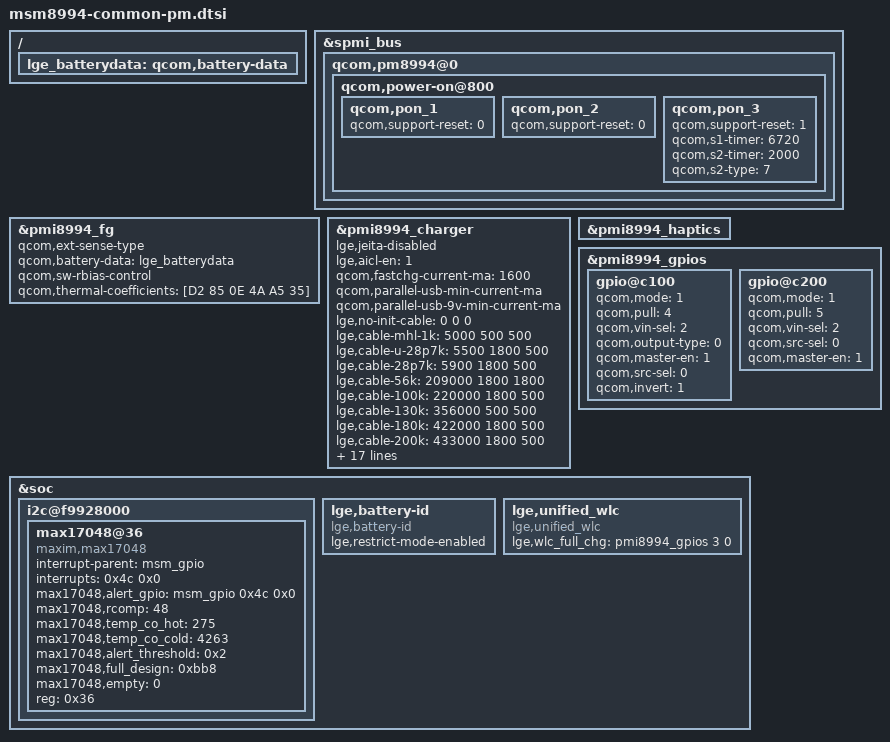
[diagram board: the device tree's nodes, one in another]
&spmi_bus {
	qcom,pm8994@0 {
		qcom,power-on@800 {
			qcom,pon_1 { /* KPD_PWR_N reset */
				status = "ok";
				qcom,support-reset = <0>;
			};

			qcom,pon_2 { /* RESIN_N reset   */
				status = "ok";
				qcom,support-reset = <0>;
			};

			qcom,pon_3 { /* KPD_PWR_N AND RESIN_N reset */
				status = "ok";
				qcom,support-reset = <1>;
				qcom,s1-timer = <6720>;
				qcom,s2-timer = <2000>;
				qcom,s2-type = <7>;
			};
		};
	};
};

/{
	lge_batterydata: qcom,battery-data {
		#include "LGE_BL51YF_LGC_3000mAh.dtsi"
		#include "LGE_BL51YF_Tocad_3000mAh.dtsi"
		#include "../qcom/batterydata-itech-3000mah.dtsi"
	};
};

&pmi8994_fg {
	status = "ok";

	qcom,ext-sense-type;
	qcom,battery-data = <&lge_batterydata>;
	qcom,sw-rbias-control;
	qcom,thermal-coefficients = [D2 85 0E 4A A5 35];
};

&pmi8994_charger {
	status = "ok";

	lge,jeita-disabled;
	lge,aicl-en = <1>;
	qcom,fastchg-current-ma = <1600>;
	qcom,parallel-usb-min-current-ma;
	qcom,parallel-usb-9v-min-current-ma;

	lge,no-init-cable = <0 0 0>;
	lge,cable-mhl-1k = <5000 500 500>;
	lge,cable-u-28p7k = <5500 1800 500>;
	lge,cable-28p7k = <5900 1800 500>;
	lge,cable-56k = <209000 1800 1800>;
	lge,cable-100k = <220000 1800 500>;
	lge,cable-130k = <356000 500 500>;
	lge,cable-180k = <422000 1800 500>;
	lge,cable-200k = <433000 1800 500>;
	lge,cable-220k = <509000 1800 500>;
	lge,cable-270k = <586000 1800 500>;
	lge,cable-330k = <763000 1800 500>;
	lge,cable-620k = <971000 1800 500>;
	lge,cable-910k = <1172000 1800 1800>;
	lge,cable-none = <1900000 1800  500>;
	qcom,iterm-ma = <100>;
	qcom,float-voltage-mv = <4400>;
	qcom,float-voltage-mv-normal-batt = <4350>;
	qcom,float-voltage-mv-high-batt = <4400>;
	qcom,resume-delta-mv = <200>;
	qcom,charge-unknown-battery;
	qcom,charging-timeout-mins = <768>;
	qcom,chg-vadc = <&pmi8994_vadc>;
	qcom,bmd-pin-src="bpd_none";
	qcom,dc-psy-type = "Wireless";
	qcom,dc-psy-ma = <900>;
};

&pmi8994_haptics {
	status = "ok";
};

&pmi8994_gpios {
	gpio@c100 {		/* GPIO 2*/
		qcom,mode = <1>;			/*DIGITAL OUT */
		qcom,pull = <4>;			/* PULL DOWN */
		qcom,vin-sel = <2>;		/* 1.8V */
		qcom,output-type = <0>; /* CMOS */
		qcom,master-en = <1>;	/* ENABLE GPIO */
		qcom,src-sel = <0>;		/* CONSTANT */
		qcom,invert = <1>;			/* INVERT ENABLE */
		status = "okay";
	};
	gpio@c200 {		/* GPIO 3 */
		qcom,mode = <1>;		/* DIGITAL OUT */
		qcom,pull = <5>;		/* No Pull */
		qcom,vin-sel = <2>;     /* 1.8 */
		qcom,src-sel = <0>;     /* CONSTANT */
		qcom,master-en = <1>;	/* ENABLE GPIO */
		status= "okay";
	};
};

&soc {
	i2c@f9928000 { /* BLSP1 QUP6 */
		status = "ok";
		max17048@36 {
			status = "ok";
			compatible = "maxim,max17048";
			interrupt-parent = <&msm_gpio>;
			interrupts = <0x4c 0x0>;
			max17048,alert_gpio = <&msm_gpio 0x4c 0x0>;
			max17048,rcomp = <48>;
			max17048,temp_co_hot = <275>;
			max17048,temp_co_cold = <4263>;
			max17048,alert_threshold = <0x2>;
			max17048,full_design = <0xbb8>;
			max17048,empty = <0>;
			reg = <0x36>;
		};
	};

	lge,battery-id{
		compatible = "lge,battery-id";
		lge,restrict-mode-enabled;
	};

	lge,unified_wlc{
		status = "ok";
		compatible = "lge,unified_wlc";
		lge,wlc_full_chg = <&pmi8994_gpios 3 0>;
	};
};

